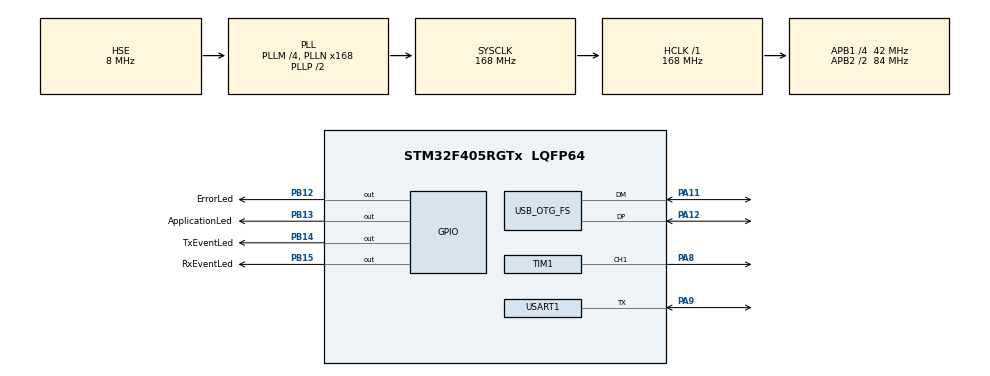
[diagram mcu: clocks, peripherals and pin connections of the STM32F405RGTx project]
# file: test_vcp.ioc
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Mcu.Family=STM32F4
Mcu.Name=STM32F405RGTx
Mcu.Package=LQFP64
NVIC.OTG_FS_IRQn=true\:0\:0\:false\:false\:true\:false\:true\:true
NVIC.PriorityGroup=NVIC_PRIORITYGROUP_4
NVIC.TIM1_BRK_TIM9_IRQn=true\:0\:0\:false\:false\:true\:true\:true\:true
NVIC.TIM1_CC_IRQn=true\:0\:0\:false\:false\:true\:true\:true\:true
NVIC.TIM1_TRG_COM_TIM11_IRQn=true\:0\:0\:false\:false\:true\:true\:true\:true
NVIC.TIM1_UP_TIM10_IRQn=true\:0\:0\:false\:false\:true\:true\:true\:true
PA11.Mode=Device_Only
PA11.Signal=USB_OTG_FS_DM
PA12.Mode=Device_Only
PA12.Signal=USB_OTG_FS_DP
PA13.Mode=Trace_Asynchronous_SW
PA13.Signal=SYS_JTMS-SWDIO
PA14.Mode=Trace_Asynchronous_SW
PA14.Signal=SYS_JTCK-SWCLK
PA8.Signal=S_TIM1_CH1
PA9.Mode=Half_duplex(single_wire_mode)
PA9.Signal=USART1_TX
PB12.GPIO_Label=ErrorLed
PB12.Signal=GPIO_Output
PB13.GPIO_Label=ApplicationLed
PB13.Signal=GPIO_Output
PB14.GPIO_Label=TxEventLed
PB14.Signal=GPIO_Output
PB15.GPIO_Label=RxEventLed
PB15.Signal=GPIO_Output
PB3.Mode=Trace_Asynchronous_SW
PB3.Signal=SYS_JTDO-SWO
PH0-OSC_IN.Mode=HSE-External-Clock-Source
PH0-OSC_IN.Signal=RCC_OSC_IN
PH1-OSC_OUT.Mode=HSE-External-Clock-Source
PH1-OSC_OUT.Signal=RCC_OSC_OUT
ProjectManager.HeapSize=0x200
ProjectManager.StackSize=0x400
ProjectManager.TargetToolchain=STM32CubeIDE
RCC.48MHZClocksFreq_Value=48000000
RCC.AHBFreq_Value=168000000
RCC.APB1CLKDivider=RCC_HCLK_DIV4
RCC.APB1Freq_Value=42000000
RCC.APB1TimFreq_Value=84000000
RCC.APB2CLKDivider=RCC_HCLK_DIV2
RCC.APB2Freq_Value=84000000
RCC.APB2TimFreq_Value=168000000
RCC.CortexFreq_Value=168000000
RCC.HCLKFreq_Value=168000000
RCC.HSE_VALUE=8000000
RCC.HSI_VALUE=16000000
RCC.LSE_VALUE=32768
RCC.PLLM=4
RCC.PLLN=168
RCC.PLLQ=7
RCC.SYSCLKFreq_VALUE=168000000
RCC.SYSCLKSource=RCC_SYSCLKSOURCE_PLLCLK
RCC.VCOOutputFreq_Value=336000000
SH.S_TIM1_CH1.0=TIM1_CH1,PWM Generation1 CH1
TIM1.Channel-PWM\ Generation1\ CH1=TIM_CHANNEL_1
USART1.VirtualMode=VM_ASYNC
USB_DEVICE.CLASS_NAME_FS=CDC
USB_DEVICE.VirtualMode-CDC_FS=Cdc
USB_DEVICE.VirtualModeFS=Cdc_FS
USB_OTG_FS.VirtualMode=Device_Only
VP_TIM1_VS_ClockSourceINT.Mode=Internal
VP_USB_DEVICE_VS_USB_DEVICE_CDC_FS.Mode=CDC_FS
board=custom

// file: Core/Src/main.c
/* USER CODE BEGIN Header */
/**
  ******************************************************************************
  * @file           : main.c
  * @brief          : Main program body
  ******************************************************************************
  * @attention
  *
  * Copyright (c) 2024 STMicroelectronics.
  * All rights reserved.
  *
  * This software is licensed under terms that can be found in the LICENSE file
  * in the root directory of this software component.
  * If no LICENSE file comes with this software, it is provided AS-IS.
  *
  ******************************************************************************
  */
/* USER CODE END Header */
#include "main.h"
#include "usb_device.h"

/* USER CODE BEGIN Includes */
#include "COM.h"
#include "StatusLeds.h"
/* USER CODE END Includes */

TIM_HandleTypeDef htim1;

UART_HandleTypeDef huart1;

/* USER CODE BEGIN PV */

StatusLeds_Descriptor_t StatusLeds_Descriptor = {
		.ApplicationLed = {ApplicationLed_GPIO_Port, ApplicationLed_Pin},
		.TxDataLed = {TxEventLed_GPIO_Port, TxEventLed_Pin},
		.RxDataLed = {RxEventLed_GPIO_Port, RxEventLed_Pin},
		.ErrorLed = {ErrorLed_GPIO_Port, ErrorLed_Pin}
};
/* USER CODE END PV */

void SystemClock_Config(void);
static void MX_GPIO_Init(void);
static void MX_USART1_UART_Init(void);
static void MX_TIM1_Init(void);

int main(void)
{

  /* MCU Configuration--------------------------------------------------------*/

  /* Reset of all peripherals, Initializes the Flash interface and the Systick. */
  HAL_Init();

  /* Configure the system clock */
  SystemClock_Config();

  /* Initialize all configured peripherals */
  MX_GPIO_Init();
  MX_USB_DEVICE_Init();
  MX_USART1_UART_Init();
  MX_TIM1_Init();
  /* USER CODE BEGIN 2 */
  COM_Init();
  StatusLeds_Init(&StatusLeds_Descriptor);
  /* USER CODE END 2 */

  /* Infinite loop */
  /* USER CODE BEGIN WHILE */
  while (1)
  {
	  COM_Process();
    /* USER CODE END WHILE */

  }
}

void SystemClock_Config(void)
{
  RCC_OscInitTypeDef RCC_OscInitStruct = {0};
  RCC_ClkInitTypeDef RCC_ClkInitStruct = {0};

  /** Configure the main internal regulator output voltage
  */
  __HAL_RCC_PWR_CLK_ENABLE();
  __HAL_PWR_VOLTAGESCALING_CONFIG(PWR_REGULATOR_VOLTAGE_SCALE1);

  /** Initializes the RCC Oscillators according to the specified parameters
  * in the RCC_OscInitTypeDef structure.
  */
  RCC_OscInitStruct.OscillatorType = RCC_OSCILLATORTYPE_HSE;
  RCC_OscInitStruct.HSEState = RCC_HSE_BYPASS;
  RCC_OscInitStruct.PLL.PLLState = RCC_PLL_ON;
  RCC_OscInitStruct.PLL.PLLSource = RCC_PLLSOURCE_HSE;
  RCC_OscInitStruct.PLL.PLLM = 4;
  RCC_OscInitStruct.PLL.PLLN = 168;
  RCC_OscInitStruct.PLL.PLLP = RCC_PLLP_DIV2;
  RCC_OscInitStruct.PLL.PLLQ = 7;
  if (HAL_RCC_OscConfig(&RCC_OscInitStruct) != HAL_OK)
  {
    Error_Handler();
  }

  /** Initializes the CPU, AHB and APB buses clocks
  */
  RCC_ClkInitStruct.ClockType = RCC_CLOCKTYPE_HCLK|RCC_CLOCKTYPE_SYSCLK
                              |RCC_CLOCKTYPE_PCLK1|RCC_CLOCKTYPE_PCLK2;
  RCC_ClkInitStruct.SYSCLKSource = RCC_SYSCLKSOURCE_PLLCLK;
  RCC_ClkInitStruct.AHBCLKDivider = RCC_SYSCLK_DIV1;
  RCC_ClkInitStruct.APB1CLKDivider = RCC_HCLK_DIV4;
  RCC_ClkInitStruct.APB2CLKDivider = RCC_HCLK_DIV2;

  if (HAL_RCC_ClockConfig(&RCC_ClkInitStruct, FLASH_LATENCY_5) != HAL_OK)
  {
    Error_Handler();
  }
}

static void MX_TIM1_Init(void)
{

  TIM_ClockConfigTypeDef sClockSourceConfig = {0};
  TIM_MasterConfigTypeDef sMasterConfig = {0};
  TIM_OC_InitTypeDef sConfigOC = {0};
  TIM_BreakDeadTimeConfigTypeDef sBreakDeadTimeConfig = {0};

  htim1.Instance = TIM1;
  htim1.Init.Prescaler = 0;
  htim1.Init.CounterMode = TIM_COUNTERMODE_UP;
  htim1.Init.Period = 65535;
  htim1.Init.ClockDivision = TIM_CLOCKDIVISION_DIV1;
  htim1.Init.RepetitionCounter = 0;
  htim1.Init.AutoReloadPreload = TIM_AUTORELOAD_PRELOAD_DISABLE;
  if (HAL_TIM_Base_Init(&htim1) != HAL_OK)
  {
    Error_Handler();
  }
  sClockSourceConfig.ClockSource = TIM_CLOCKSOURCE_INTERNAL;
  if (HAL_TIM_ConfigClockSource(&htim1, &sClockSourceConfig) != HAL_OK)
  {
    Error_Handler();
  }
  if (HAL_TIM_PWM_Init(&htim1) != HAL_OK)
  {
    Error_Handler();
  }
  sMasterConfig.MasterOutputTrigger = TIM_TRGO_RESET;
  sMasterConfig.MasterSlaveMode = TIM_MASTERSLAVEMODE_DISABLE;
  if (HAL_TIMEx_MasterConfigSynchronization(&htim1, &sMasterConfig) != HAL_OK)
  {
    Error_Handler();
  }
  sConfigOC.OCMode = TIM_OCMODE_PWM1;
  sConfigOC.Pulse = 0;
  sConfigOC.OCPolarity = TIM_OCPOLARITY_HIGH;
  sConfigOC.OCNPolarity = TIM_OCNPOLARITY_HIGH;
  sConfigOC.OCFastMode = TIM_OCFAST_DISABLE;
  sConfigOC.OCIdleState = TIM_OCIDLESTATE_RESET;
  sConfigOC.OCNIdleState = TIM_OCNIDLESTATE_RESET;
  if (HAL_TIM_PWM_ConfigChannel(&htim1, &sConfigOC, TIM_CHANNEL_1) != HAL_OK)
  {
    Error_Handler();
  }
  sBreakDeadTimeConfig.OffStateRunMode = TIM_OSSR_DISABLE;
  sBreakDeadTimeConfig.OffStateIDLEMode = TIM_OSSI_DISABLE;
  sBreakDeadTimeConfig.LockLevel = TIM_LOCKLEVEL_OFF;
  sBreakDeadTimeConfig.DeadTime = 0;
  sBreakDeadTimeConfig.BreakState = TIM_BREAK_DISABLE;
  sBreakDeadTimeConfig.BreakPolarity = TIM_BREAKPOLARITY_HIGH;
  sBreakDeadTimeConfig.AutomaticOutput = TIM_AUTOMATICOUTPUT_DISABLE;
  if (HAL_TIMEx_ConfigBreakDeadTime(&htim1, &sBreakDeadTimeConfig) != HAL_OK)
  {
    Error_Handler();
  }
  HAL_TIM_MspPostInit(&htim1);

}

static void MX_USART1_UART_Init(void)
{

  huart1.Instance = USART1;
  huart1.Init.BaudRate = 115200;
  huart1.Init.WordLength = UART_WORDLENGTH_8B;
  huart1.Init.StopBits = UART_STOPBITS_1;
  huart1.Init.Parity = UART_PARITY_NONE;
  huart1.Init.Mode = UART_MODE_TX_RX;
  huart1.Init.HwFlowCtl = UART_HWCONTROL_NONE;
  huart1.Init.OverSampling = UART_OVERSAMPLING_16;
  if (HAL_HalfDuplex_Init(&huart1) != HAL_OK)
  {
    Error_Handler();
  }

}

static void MX_GPIO_Init(void)
{
  GPIO_InitTypeDef GPIO_InitStruct = {0};

  /* GPIO Ports Clock Enable */
  __HAL_RCC_GPIOH_CLK_ENABLE();
  __HAL_RCC_GPIOB_CLK_ENABLE();
  __HAL_RCC_GPIOA_CLK_ENABLE();

  /*Configure GPIO pin Output Level */
  HAL_GPIO_WritePin(GPIOB, ErrorLed_Pin|ApplicationLed_Pin|TxEventLed_Pin|RxEventLed_Pin, GPIO_PIN_RESET);

  /*Configure GPIO pins : ErrorLed_Pin ApplicationLed_Pin TxEventLed_Pin RxEventLed_Pin */
  GPIO_InitStruct.Pin = ErrorLed_Pin|ApplicationLed_Pin|TxEventLed_Pin|RxEventLed_Pin;
  GPIO_InitStruct.Mode = GPIO_MODE_OUTPUT_PP;
  GPIO_InitStruct.Pull = GPIO_NOPULL;
  GPIO_InitStruct.Speed = GPIO_SPEED_FREQ_LOW;
  HAL_GPIO_Init(GPIOB, &GPIO_InitStruct);

}

void Error_Handler(void)
{
  __disable_irq();
  while (1)
  {
  }
}
